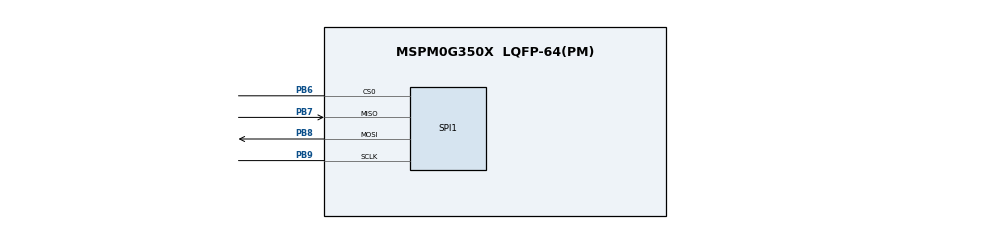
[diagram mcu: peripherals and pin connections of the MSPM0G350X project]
// @cliArgs --device "MSPM0G350X" --package "LQFP-64(PM)" --part "Default"
// @cliArgs --board /ti/boards/LP_MSPM0G3507 --rtos nortos

/**
 * Import the modules used in this configuration.
 */
const GPIO   = scripting.addModule("/ti/driverlib/GPIO", {}, false);
const GPIO1  = GPIO.addInstance();
const GPIO2  = GPIO.addInstance();
const GPIO3  = GPIO.addInstance();
const SPI    = scripting.addModule("/ti/driverlib/SPI", {}, false);
const SPI1   = SPI.addInstance();
const SYSCTL = scripting.addModule("/ti/driverlib/SYSCTL");

/**
 * Write custom configuration values to the imported modules.
 */
const gate7  = system.clockTree["MFCLKGATE"];
gate7.enable = true;

GPIO1.$name                              = "GPIO_Button";
GPIO1.associatedPins[0].$name            = "PIN_0";
GPIO1.associatedPins[0].direction        = "INPUT";
GPIO1.associatedPins[0].assignedPort     = "PORTB";
GPIO1.associatedPins[0].assignedPin      = "21";
GPIO1.associatedPins[0].internalResistor = "PULL_UP";

const Board = scripting.addModule("/ti/driverlib/Board", {}, false);

GPIO2.$name                          = "GPIO_BSL";
GPIO2.associatedPins.create(2);
GPIO2.associatedPins[0].$name        = "NRST";
GPIO2.associatedPins[0].initialValue = "SET";
GPIO2.associatedPins[0].assignedPort = "PORTB";
GPIO2.associatedPins[0].assignedPin  = "0";
GPIO2.associatedPins[1].$name        = "Invoke";
GPIO2.associatedPins[1].assignedPort = "PORTB";
GPIO2.associatedPins[1].assignedPin  = "16";

GPIO3.$name                          = "GPIO_LED";
GPIO3.associatedPins.create(2);
GPIO3.associatedPins[0].$name        = "PA0";
GPIO3.associatedPins[0].assignedPort = "PORTA";
GPIO3.associatedPins[0].assignedPin  = "0";
GPIO3.associatedPins[0].initialValue = "SET";
GPIO3.associatedPins[1].$name        = "Error";
GPIO3.associatedPins[1].assignedPort = "PORTB";
GPIO3.associatedPins[1].assignedPin  = "27";

SPI1.$name                      = "SPI_0";
SPI1.spiClkSrc                  = "MFCLK";
SPI1.rxFifoThreshold            = "DL_SPI_RX_FIFO_LEVEL_ONE_FRAME";
SPI1.txFifoThreshold            = "DL_SPI_TX_FIFO_LEVEL_ONE_FRAME";
SPI1.targetBitRate              = 1000000;
SPI1.peripheral.$assign         = "SPI1";
SPI1.peripheral.sclkPin.$assign = "PB9";
SPI1.peripheral.mosiPin.$assign = "PB8";
SPI1.peripheral.misoPin.$assign = "PB7";
SPI1.peripheral.cs0Pin.$assign  = "PB6";

SYSCTL.MFCLKEn = true;
